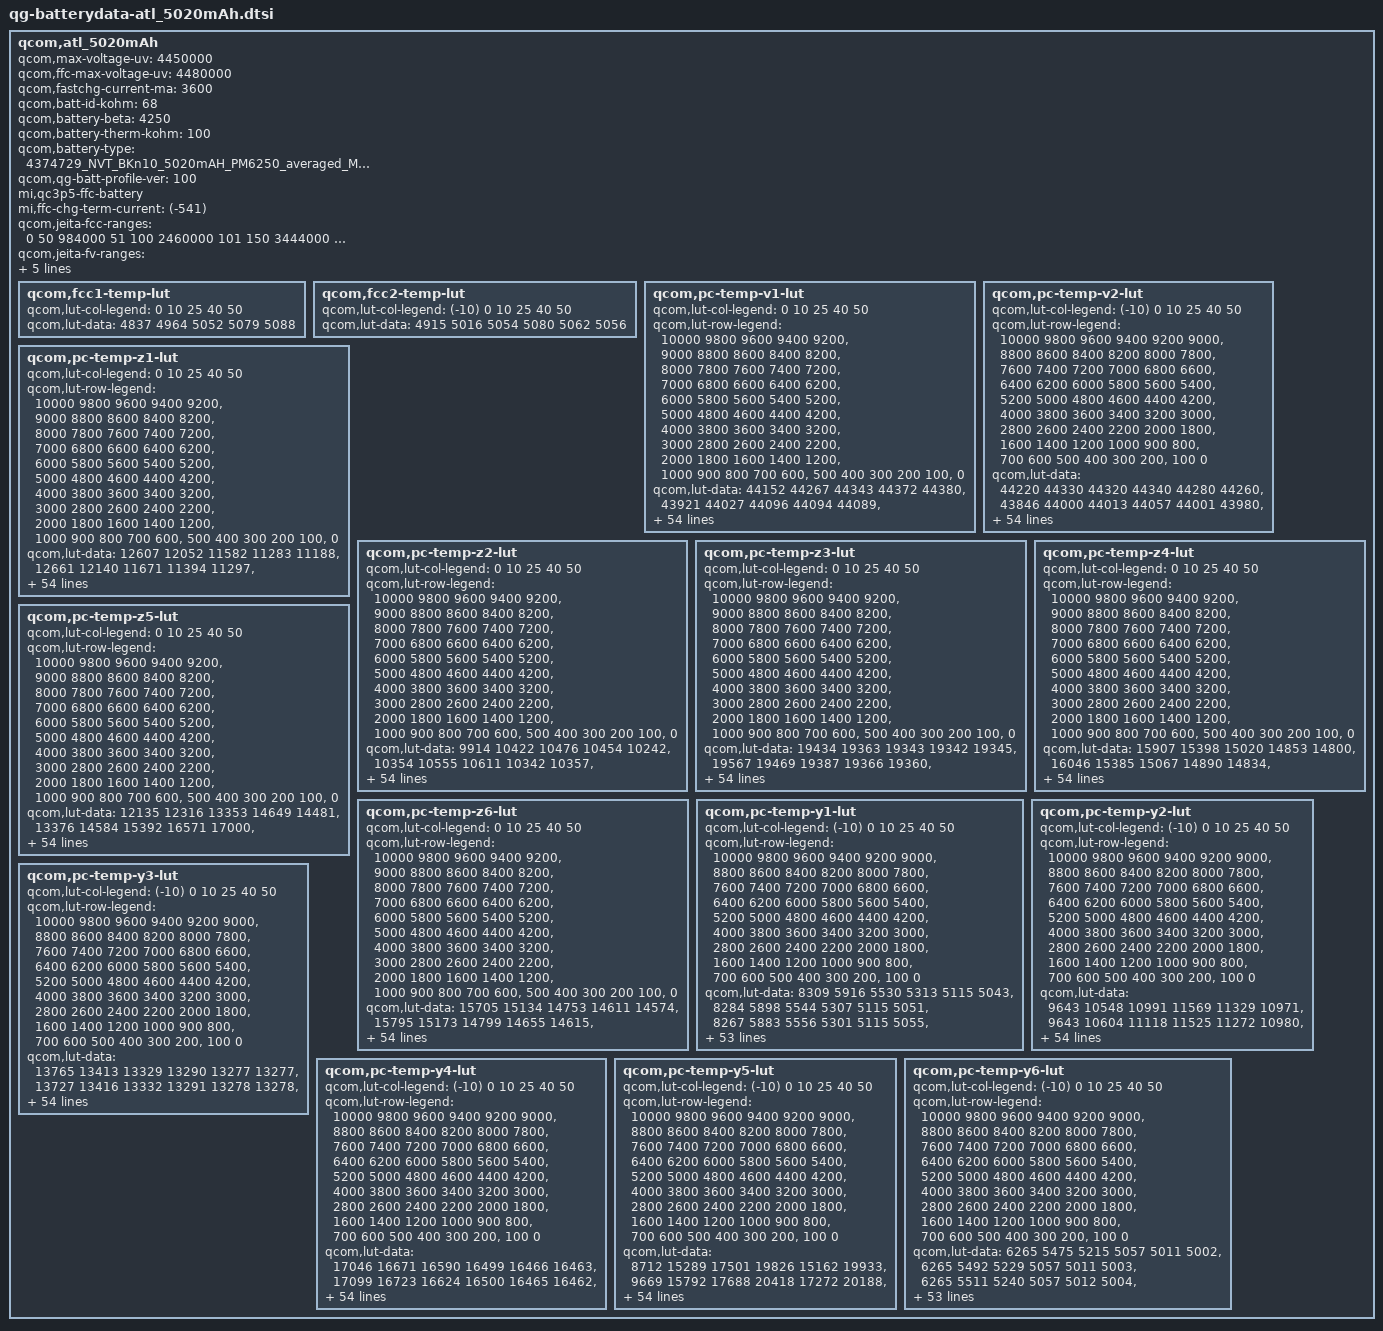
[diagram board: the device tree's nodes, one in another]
/*
 * Copyright (c) 2019, The Linux Foundation. All rights reserved.
 * Copyright (C) 2020 XiaoMi, Inc.
 *
 * This program is free software; you can redistribute it and/or modify
 * it under the terms of the GNU General Public License version 2 and
 * only version 2 as published by the Free Software Foundation.
 *
 * This program is distributed in the hope that it will be useful,
 * but WITHOUT ANY WARRANTY; without even the implied warranty of
 * MERCHANTABILITY or FITNESS FOR A PARTICULAR PURPOSE.  See the
 * GNU General Public License for more details.
 */

qcom,atl_5020mAh {
	qcom,max-voltage-uv = <4450000>;
	qcom,ffc-max-voltage-uv = <4480000>;
	qcom,fastchg-current-ma = <3600>;
	qcom,batt-id-kohm = <68>;
	qcom,battery-beta = <4250>;
	qcom,battery-therm-kohm = <100>;
	qcom,battery-type =
		"4374729_NVT_BKn10_5020mAH_PM6250_averaged_MasterSlave_Dec27th2019";
	qcom,qg-batt-profile-ver = <100>;
	mi,qc3p5-ffc-battery;
	mi,ffc-chg-term-current = <(-541)>;

	qcom,jeita-fcc-ranges = <0   50   984000
				 51  100  2460000
				 101 150  3444000
				 151 450  3600000
				 451 600  2460000>;

	qcom,jeita-fv-ranges = <0   50   4450000
				51  100  4450000
				101 150  4450000
				151 450  4480000
				451 600  4100000>;

	qcom,step-chg-ranges = <3001000  4250000  3600000
				4250001  4430000  3300000
				4430001  4450000  3000000>;

	qcom,dynamic-fv-ranges = <0   100  4480000
				 101  200  4460000
				 201  300  4440000
				 301  400  4420000
				 401  500  4400000>;

	qcom,fcc1-temp-lut {
		qcom,lut-col-legend = <0 10 25 40 50>;
		qcom,lut-data = <4837 4964 5052 5079 5088>;
	};

	qcom,fcc2-temp-lut {
		qcom,lut-col-legend = <(-10) 0 10 25 40 50>;
		qcom,lut-data = <4915 5016 5054 5080 5062 5056>;
	};

	qcom,pc-temp-v1-lut {
		qcom,lut-col-legend = <0 10 25 40 50>;
		qcom,lut-row-legend = <10000 9800 9600 9400 9200>,
			<9000 8800 8600 8400 8200>,
			<8000 7800 7600 7400 7200>,
			<7000 6800 6600 6400 6200>,
			<6000 5800 5600 5400 5200>,
			<5000 4800 4600 4400 4200>,
			<4000 3800 3600 3400 3200>,
			<3000 2800 2600 2400 2200>,
			<2000 1800 1600 1400 1200>,
			<1000 900 800 700 600>,
			<500 400 300 200 100>,
			<0>;
		qcom,lut-data = <44152 44267 44343 44372 44380>,
			<43921 44027 44096 44094 44089>,
			<43687 43792 43869 43868 43860>,
			<43451 43567 43645 43652 43645>,
			<43214 43345 43421 43432 43425>,
			<42975 43113 43196 43211 43206>,
			<42736 42875 42961 42982 42978>,
			<42496 42634 42718 42743 42740>,
			<42258 42391 42475 42501 42499>,
			<42030 42148 42231 42259 42257>,
			<41810 41912 41990 42017 42015>,
			<41592 41680 41754 41779 41777>,
			<41369 41454 41523 41544 41543>,
			<41146 41234 41298 41315 41314>,
			<40935 41020 41077 41092 41093>,
			<40737 40812 40864 40876 40879>,
			<40544 40609 40658 40671 40672>,
			<40349 40416 40459 40474 40470>,
			<40154 40237 40273 40287 40279>,
			<39976 40067 40106 40116 40107>,
			<39825 39895 39932 39943 39936>,
			<39681 39728 39708 39723 39719>,
			<39529 39546 39451 39454 39452>,
			<39370 39299 39240 39232 39230>,
			<39201 39010 39070 39073 39076>,
			<39000 38831 38926 38938 38946>,
			<38791 38741 38812 38814 38822>,
			<38652 38672 38715 38701 38707>,
			<38561 38593 38623 38599 38601>,
			<38491 38517 38532 38505 38503>,
			<38436 38446 38450 38420 38414>,
			<38392 38377 38377 38342 38332>,
			<38350 38314 38311 38269 38256>,
			<38308 38260 38252 38203 38185>,
			<38269 38214 38201 38144 38121>,
			<38235 38171 38152 38086 38057>,
			<38206 38137 38104 38027 37990>,
			<38170 38100 38057 37966 37920>,
			<38117 38044 37993 37891 37837>,
			<38046 37961 37903 37794 37731>,
			<37956 37863 37798 37686 37615>,
			<37830 37747 37682 37573 37496>,
			<37688 37608 37547 37446 37365>,
			<37527 37434 37382 37283 37194>,
			<37361 37270 37222 37135 37057>,
			<37230 37154 37114 37044 36978>,
			<37200 37121 37077 37013 36950>,
			<37157 37092 37052 36993 36929>,
			<37121 37069 37035 36971 36907>,
			<37087 37030 36994 36919 36844>,
			<37017 36855 36782 36672 36572>,
			<36725 36420 36346 36229 36131>,
			<36210 35834 35768 35651 35549>,
			<35519 35017 34971 34860 34755>,
			<34357 33626 33725 33620 33511>,
			<30000 30000 30000 30000 30000>;
	};

	qcom,pc-temp-v2-lut {
		qcom,lut-col-legend = <(-10) 0 10 25 40 50>;
		qcom,lut-row-legend = <10000 9800 9600 9400 9200 9000>,
			<8800 8600 8400 8200 8000 7800>,
			<7600 7400 7200 7000 6800 6600>,
			<6400 6200 6000 5800 5600 5400>,
			<5200 5000 4800 4600 4400 4200>,
			<4000 3800 3600 3400 3200 3000>,
			<2800 2600 2400 2200 2000 1800>,
			<1600 1400 1200 1000 900 800>,
			<700 600 500 400 300 200>,
			<100 0>;
		qcom,lut-data = <44220 44330 44320 44340 44280 44260>,
			<43846 44000 44013 44057 44001 43980>,
			<43513 43701 43733 43793 43739 43718>,
			<43232 43441 43482 43554 43500 43478>,
			<42999 43217 43263 43338 43283 43261>,
			<42771 42994 43039 43117 43062 43040>,
			<42514 42754 42798 42879 42826 42806>,
			<42248 42509 42550 42635 42584 42567>,
			<42008 42260 42302 42390 42343 42327>,
			<41792 42005 42053 42144 42099 42084>,
			<41586 41753 41808 41903 41859 41845>,
			<41390 41497 41570 41665 41622 41608>,
			<41202 41251 41338 41431 41389 41376>,
			<40989 41055 41111 41202 41160 41148>,
			<40736 40905 40890 40977 40938 40926>,
			<40459 40735 40677 40759 40723 40712>,
			<40159 40484 40477 40550 40517 40505>,
			<39832 40195 40280 40347 40319 40305>,
			<39546 39940 40081 40158 40134 40120>,
			<39320 39709 39880 39979 39958 39945>,
			<39116 39483 39664 39777 39766 39757>,
			<38910 39251 39413 39531 39534 39533>,
			<38704 39027 39163 39284 39297 39305>,
			<38536 38831 38960 39074 39090 39100>,
			<38415 38656 38783 38884 38900 38907>,
			<38317 38495 38626 38726 38742 38748>,
			<38238 38334 38486 38597 38614 38619>,
			<38174 38190 38359 38484 38504 38508>,
			<38115 38105 38239 38377 38400 38403>,
			<38056 38050 38127 38279 38304 38305>,
			<38000 38002 38034 38190 38217 38217>,
			<37943 37954 37956 38109 38141 38139>,
			<37887 37908 37893 38033 38068 38064>,
			<37828 37861 37850 37961 37997 37991>,
			<37768 37816 37818 37893 37927 37919>,
			<37705 37767 37782 37821 37846 37832>,
			<37637 37711 37740 37745 37746 37714>,
			<37563 37649 37692 37666 37641 37592>,
			<37484 37577 37629 37583 37544 37492>,
			<37393 37493 37549 37496 37448 37400>,
			<37292 37398 37451 37406 37355 37309>,
			<37194 37290 37318 37312 37268 37222>,
			<37099 37166 37170 37195 37158 37111>,
			<37014 37022 37006 37053 37013 36956>,
			<36945 36883 36850 36919 36889 36836>,
			<36877 36773 36748 36858 36839 36788>,
			<36840 36732 36709 36844 36830 36778>,
			<36793 36702 36665 36822 36815 36763>,
			<36742 36663 36618 36781 36790 36734>,
			<36679 36622 36519 36692 36704 36626>,
			<36584 36523 36278 36388 36388 36294>,
			<36412 36207 35819 35867 35884 35781>,
			<36107 35577 35149 35176 35223 35104>,
			<35532 34601 34139 34194 34286 34157>,
			<34689 33433 32559 32713 32910 32798>,
			<33552 31613 28186 27744 27717 27697>;
	};

	qcom,pc-temp-z1-lut {
		qcom,lut-col-legend = <0 10 25 40 50>;
		qcom,lut-row-legend = <10000 9800 9600 9400 9200>,
			<9000 8800 8600 8400 8200>,
			<8000 7800 7600 7400 7200>,
			<7000 6800 6600 6400 6200>,
			<6000 5800 5600 5400 5200>,
			<5000 4800 4600 4400 4200>,
			<4000 3800 3600 3400 3200>,
			<3000 2800 2600 2400 2200>,
			<2000 1800 1600 1400 1200>,
			<1000 900 800 700 600>,
			<500 400 300 200 100>,
			<0>;
		qcom,lut-data = <12607 12052 11582 11283 11188>,
			<12661 12140 11671 11394 11297>,
			<12733 12181 11696 11414 11316>,
			<12787 12180 11702 11420 11325>,
			<12788 12178 11703 11420 11329>,
			<12775 12173 11703 11419 11331>,
			<12760 12156 11701 11418 11333>,
			<12739 12141 11691 11418 11335>,
			<12714 12133 11683 11418 11336>,
			<12692 12127 11674 11417 11338>,
			<12669 12120 11668 11417 11339>,
			<12657 12110 11669 11415 11340>,
			<12661 12103 11674 11413 11339>,
			<12668 12106 11675 11411 11339>,
			<12670 12113 11673 11412 11339>,
			<12669 12114 11669 11415 11340>,
			<12666 12107 11668 11415 11340>,
			<12663 12100 11667 11414 11341>,
			<12660 12103 11668 11414 11342>,
			<12656 12108 11673 11415 11343>,
			<12651 12110 11679 11417 11345>,
			<12646 12104 11679 11418 11346>,
			<12646 12098 11678 11419 11347>,
			<12650 12100 11678 11420 11348>,
			<12656 12104 11679 11423 11350>,
			<12662 12106 11682 11426 11352>,
			<12668 12099 11685 11428 11354>,
			<12669 12092 11691 11431 11356>,
			<12668 12096 11695 11433 11357>,
			<12667 12110 11698 11435 11360>,
			<12671 12119 11701 11438 11363>,
			<12683 12125 11704 11442 11367>,
			<12697 12129 11707 11446 11370>,
			<12712 12128 11711 11449 11373>,
			<12725 12125 11717 11452 11376>,
			<12730 12124 11722 11455 11379>,
			<12732 12128 11726 11457 11381>,
			<12733 12138 11731 11460 11384>,
			<12731 12153 11736 11464 11386>,
			<12729 12177 11742 11469 11388>,
			<12733 12198 11749 11474 11390>,
			<12778 12213 11758 11477 11393>,
			<12802 12220 11766 11479 11396>,
			<12807 12217 11768 11482 11399>,
			<12828 12237 11775 11486 11399>,
			<12810 12235 11790 11489 11400>,
			<12836 12215 11786 11488 11398>,
			<12810 12220 11790 11486 11399>,
			<12832 12248 11796 11490 11402>,
			<12842 12253 11793 11496 11405>,
			<12810 12233 11805 11498 11408>,
			<12879 12264 11818 11506 11413>,
			<12874 12261 11827 11517 11421>,
			<12894 12323 11843 11526 11432>,
			<12894 12323 11843 11526 11432>,
			<12894 12323 11843 11526 11432>;
	};

	qcom,pc-temp-z2-lut {
		qcom,lut-col-legend = <0 10 25 40 50>;
		qcom,lut-row-legend = <10000 9800 9600 9400 9200>,
			<9000 8800 8600 8400 8200>,
			<8000 7800 7600 7400 7200>,
			<7000 6800 6600 6400 6200>,
			<6000 5800 5600 5400 5200>,
			<5000 4800 4600 4400 4200>,
			<4000 3800 3600 3400 3200>,
			<3000 2800 2600 2400 2200>,
			<2000 1800 1600 1400 1200>,
			<1000 900 800 700 600>,
			<500 400 300 200 100>,
			<0>;
		qcom,lut-data = <9914 10422 10476 10454 10242>,
			<10354 10555 10611 10342 10357>,
			<10378 10613 10687 10471 10344>,
			<10387 10598 10709 10572 10333>,
			<10379 10565 10669 10552 10335>,
			<10345 10532 10610 10502 10341>,
			<10316 10493 10576 10460 10342>,
			<10296 10461 10551 10421 10338>,
			<10282 10442 10532 10394 10331>,
			<10306 10428 10514 10379 10310>,
			<10460 10422 10503 10370 10279>,
			<10577 10420 10509 10371 10272>,
			<10496 10418 10530 10388 10274>,
			<10329 10434 10539 10398 10275>,
			<10273 10470 10540 10394 10260>,
			<10283 10498 10541 10383 10235>,
			<10299 10518 10556 10364 10232>,
			<10317 10538 10596 10324 10239>,
			<10342 10560 10618 10304 10250>,
			<10366 10582 10623 10314 10262>,
			<10389 10598 10628 10338 10280>,
			<10411 10609 10673 10426 10352>,
			<10432 10619 10766 10654 10561>,
			<10455 10635 10790 10756 10667>,
			<10468 10653 10715 10595 10559>,
			<10469 10658 10646 10410 10423>,
			<10470 10642 10651 10441 10421>,
			<10472 10626 10669 10586 10467>,
			<10480 10626 10674 10644 10485>,
			<10490 10627 10674 10573 10410>,
			<10496 10629 10672 10484 10308>,
			<10501 10632 10662 10439 10250>,
			<10506 10635 10644 10406 10206>,
			<10514 10643 10640 10398 10195>,
			<10522 10657 10652 10411 10226>,
			<10529 10672 10671 10432 10275>,
			<10537 10685 10699 10462 10332>,
			<10546 10699 10737 10506 10398>,
			<10565 10716 10772 10555 10442>,
			<10591 10737 10810 10621 10468>,
			<10613 10752 10831 10669 10488>,
			<10630 10757 10822 10683 10503>,
			<10652 10763 10809 10690 10517>,
			<10684 10778 10814 10683 10545>,
			<10988 10899 10842 10666 10522>,
			<10840 10977 10915 10645 10459>,
			<10408 11008 10880 10566 10447>,
			<10530 11042 10850 10589 10486>,
			<10349 11286 10861 10594 10473>,
			<10364 11465 10902 10684 10585>,
			<10679 11364 10896 10598 10460>,
			<10244 11213 10871 10415 10255>,
			<10589 11080 10777 10339 10196>,
			<10353 10777 10717 10315 10129>,
			<10353 10777 10717 10315 10129>,
			<10353 10777 10717 10315 10129>;
	};

	qcom,pc-temp-z3-lut {
		qcom,lut-col-legend = <0 10 25 40 50>;
		qcom,lut-row-legend = <10000 9800 9600 9400 9200>,
			<9000 8800 8600 8400 8200>,
			<8000 7800 7600 7400 7200>,
			<7000 6800 6600 6400 6200>,
			<6000 5800 5600 5400 5200>,
			<5000 4800 4600 4400 4200>,
			<4000 3800 3600 3400 3200>,
			<3000 2800 2600 2400 2200>,
			<2000 1800 1600 1400 1200>,
			<1000 900 800 700 600>,
			<500 400 300 200 100>,
			<0>;
		qcom,lut-data = <19434 19363 19343 19342 19345>,
			<19567 19469 19387 19366 19360>,
			<19647 19529 19412 19377 19368>,
			<19698 19548 19426 19385 19373>,
			<19719 19559 19433 19392 19379>,
			<19732 19560 19438 19398 19384>,
			<19737 19555 19440 19401 19389>,
			<19734 19552 19442 19404 19393>,
			<19729 19552 19442 19405 19395>,
			<19730 19551 19442 19403 19395>,
			<19743 19551 19441 19400 19392>,
			<19753 19546 19438 19398 19390>,
			<19738 19540 19429 19395 19387>,
			<19703 19532 19422 19393 19384>,
			<19684 19523 19419 19390 19381>,
			<19676 19516 19416 19388 19376>,
			<19671 19513 19414 19383 19373>,
			<19663 19509 19412 19377 19370>,
			<19654 19503 19410 19371 19367>,
			<19646 19495 19406 19366 19362>,
			<19636 19493 19403 19363 19358>,
			<19628 19495 19408 19366 19358>,
			<19627 19497 19422 19380 19365>,
			<19629 19502 19426 19386 19368>,
			<19632 19508 19412 19373 19364>,
			<19637 19510 19399 19359 19359>,
			<19645 19502 19400 19367 19365>,
			<19647 19493 19404 19394 19388>,
			<19644 19492 19410 19405 19399>,
			<19640 19493 19419 19402 19395>,
			<19635 19493 19426 19397 19389>,
			<19628 19497 19425 19392 19384>,
			<19622 19500 19421 19386 19378>,
			<19618 19500 19418 19380 19371>,
			<19615 19498 19413 19374 19363>,
			<19611 19496 19409 19368 19355>,
			<19605 19493 19405 19364 19349>,
			<19599 19489 19401 19359 19344>,
			<19592 19485 19399 19358 19343>,
			<19585 19481 19398 19359 19344>,
			<19579 19476 19397 19359 19346>,
			<19572 19468 19394 19359 19349>,
			<19563 19462 19390 19359 19353>,
			<19548 19459 19387 19360 19357>,
			<19479 19439 19379 19359 19356>,
			<19414 19417 19367 19346 19346>,
			<19262 19402 19366 19344 19342>,
			<19262 19392 19366 19336 19329>,
			<19263 19326 19356 19334 19327>,
			<19263 19312 19346 19329 19322>,
			<19261 19322 19345 19343 19338>,
			<19268 19330 19361 19358 19349>,
			<19313 19320 19350 19357 19351>,
			<19331 19336 19343 19352 19352>,
			<19331 19336 19343 19352 19352>,
			<19331 19336 19343 19352 19352>;
	};

	qcom,pc-temp-z4-lut {
		qcom,lut-col-legend = <0 10 25 40 50>;
		qcom,lut-row-legend = <10000 9800 9600 9400 9200>,
			<9000 8800 8600 8400 8200>,
			<8000 7800 7600 7400 7200>,
			<7000 6800 6600 6400 6200>,
			<6000 5800 5600 5400 5200>,
			<5000 4800 4600 4400 4200>,
			<4000 3800 3600 3400 3200>,
			<3000 2800 2600 2400 2200>,
			<2000 1800 1600 1400 1200>,
			<1000 900 800 700 600>,
			<500 400 300 200 100>,
			<0>;
		qcom,lut-data = <15907 15398 15020 14853 14800>,
			<16046 15385 15067 14890 14834>,
			<15895 15354 15005 14862 14821>,
			<15678 15257 14946 14828 14803>,
			<15511 15110 14899 14803 14786>,
			<15355 15018 14857 14780 14768>,
			<15228 14955 14823 14761 14752>,
			<15136 14905 14794 14744 14736>,
			<15058 14862 14770 14730 14723>,
			<14974 14826 14746 14716 14712>,
			<14877 14798 14729 14704 14703>,
			<14821 14774 14720 14697 14698>,
			<14823 14757 14716 14692 14695>,
			<14827 14744 14711 14688 14692>,
			<14827 14733 14706 14684 14689>,
			<14807 14729 14701 14681 14685>,
			<14784 14726 14697 14678 14682>,
			<14776 14724 14692 14676 14679>,
			<14771 14720 14688 14674 14676>,
			<14765 14715 14686 14670 14670>,
			<14753 14714 14684 14665 14664>,
			<14740 14714 14699 14676 14676>,
			<14737 14714 14740 14722 14731>,
			<14736 14744 14772 14756 14762>,
			<14735 14818 14798 14774 14763>,
			<14763 14845 14813 14785 14764>,
			<14815 14830 14806 14772 14752>,
			<14831 14809 14783 14729 14712>,
			<14828 14792 14762 14704 14689>,
			<14823 14775 14740 14696 14684>,
			<14815 14761 14724 14690 14681>,
			<14801 14750 14718 14687 14677>,
			<14788 14742 14714 14684 14674>,
			<14777 14738 14712 14682 14671>,
			<14767 14735 14709 14679 14668>,
			<14757 14732 14708 14677 14667>,
			<14746 14727 14706 14678 14667>,
			<14736 14723 14705 14678 14669>,
			<14726 14720 14704 14680 14672>,
			<14716 14718 14705 14689 14682>,
			<14710 14716 14705 14696 14690>,
			<14707 14707 14700 14690 14685>,
			<14702 14696 14690 14682 14677>,
			<14690 14686 14684 14681 14681>,
			<14686 14667 14670 14671 14674>,
			<14741 14660 14655 14658 14653>,
			<14903 14668 14649 14654 14648>,
			<14898 14670 14639 14647 14646>,
			<14895 14739 14636 14631 14630>,
			<14892 14751 14638 14627 14623>,
			<14886 14743 14654 14642 14650>,
			<14892 14747 14649 14644 14654>,
			<14867 14767 14661 14649 14659>,
			<14873 14763 14674 14655 14659>,
			<14873 14763 14674 14655 14659>,
			<14873 14763 14674 14655 14659>;
	};

	qcom,pc-temp-z5-lut {
		qcom,lut-col-legend = <0 10 25 40 50>;
		qcom,lut-row-legend = <10000 9800 9600 9400 9200>,
			<9000 8800 8600 8400 8200>,
			<8000 7800 7600 7400 7200>,
			<7000 6800 6600 6400 6200>,
			<6000 5800 5600 5400 5200>,
			<5000 4800 4600 4400 4200>,
			<4000 3800 3600 3400 3200>,
			<3000 2800 2600 2400 2200>,
			<2000 1800 1600 1400 1200>,
			<1000 900 800 700 600>,
			<500 400 300 200 100>,
			<0>;
		qcom,lut-data = <12135 12316 13353 14649 14481>,
			<13376 14584 15392 16571 17000>,
			<14249 16199 16950 17958 18491>,
			<14976 17166 18009 19044 19599>,
			<15619 17875 18637 20022 20802>,
			<16173 18433 19169 20873 21940>,
			<16759 18829 19849 21686 23189>,
			<17367 19323 20620 22430 24592>,
			<18061 20315 21550 23232 26014>,
			<19204 21702 23074 24258 27469>,
			<21295 23005 24274 25365 28867>,
			<22654 24286 24355 26265 29829>,
			<22684 25474 24343 27003 30563>,
			<22688 26462 24360 27759 31008>,
			<22776 27352 24861 28840 31153>,
			<23894 28320 25723 29784 31256>,
			<25445 29568 26919 29680 31671>,
			<26620 30355 28577 28664 33059>,
			<27716 29894 29651 28110 34511>,
			<28585 28834 30084 28355 35704>,
			<29076 28849 30621 28958 36792>,
			<29576 33485 34910 31453 37690>,
			<31458 39139 43758 38162 38519>,
			<37823 42577 45780 41008 38731>,
			<44754 45381 34371 31115 30644>,
			<50722 45766 23799 19709 20486>,
			<56058 38419 23121 20097 20879>,
			<57096 30950 22946 24725 26395>,
			<53213 30431 23230 27622 29837>,
			<48213 30488 26702 28650 30861>,
			<44646 30693 30765 29389 31534>,
			<41402 33632 33042 30122 32142>,
			<40184 37841 34862 30777 32668>,
			<40159 40871 36440 31318 32764>,
			<40142 43602 38049 31844 31624>,
			<39967 44905 38932 32159 30172>,
			<39325 45306 38924 32175 29303>,
			<38901 45516 38858 32177 28612>,
			<39925 45316 38749 32190 28439>,
			<41734 44242 38478 32273 28529>,
			<42131 42641 38016 32340 28712>,
			<40965 38660 36632 31274 29331>,
			<39523 36123 34759 29745 30798>,
			<37869 38661 33507 31709 35026>,
			<30789 38277 33765 32759 36491>,
			<26325 32599 30859 27105 30115>,
			<11847 24462 31199 25375 26420>,
			<11818 22080 33752 23369 21764>,
			<11782 14052 28207 28248 26665>,
			<11759 13373 24273 28193 28741>,
			<11759 13921 21449 29126 27877>,
			<11914 14034 23653 29052 24729>,
			<12471 13256 19478 25138 21862>,
			<12955 13819 17104 19942 19131>,
			<12955 13819 17104 19942 19131>,
			<12955 13819 17104 19942 19131>;
	};

	qcom,pc-temp-z6-lut {
		qcom,lut-col-legend = <0 10 25 40 50>;
		qcom,lut-row-legend = <10000 9800 9600 9400 9200>,
			<9000 8800 8600 8400 8200>,
			<8000 7800 7600 7400 7200>,
			<7000 6800 6600 6400 6200>,
			<6000 5800 5600 5400 5200>,
			<5000 4800 4600 4400 4200>,
			<4000 3800 3600 3400 3200>,
			<3000 2800 2600 2400 2200>,
			<2000 1800 1600 1400 1200>,
			<1000 900 800 700 600>,
			<500 400 300 200 100>,
			<0>;
		qcom,lut-data = <15705 15134 14753 14611 14574>,
			<15795 15173 14799 14655 14615>,
			<15740 15182 14791 14651 14614>,
			<15657 15144 14780 14647 14614>,
			<15581 15071 14762 14641 14612>,
			<15498 15020 14742 14633 14607>,
			<15425 14981 14727 14627 14603>,
			<15364 14949 14713 14621 14600>,
			<15311 14922 14701 14615 14596>,
			<15266 14900 14690 14609 14591>,
			<15227 14881 14680 14602 14586>,
			<15196 14864 14673 14597 14582>,
			<15172 14850 14666 14593 14580>,
			<15153 14838 14661 14590 14577>,
			<15135 14828 14656 14587 14573>,
			<15116 14821 14652 14584 14569>,
			<15100 14817 14649 14580 14565>,
			<15090 14813 14646 14575 14562>,
			<15083 14807 14643 14571 14559>,
			<15075 14802 14641 14567 14554>,
			<15065 14800 14639 14563 14549>,
			<15056 14802 14649 14571 14555>,
			<15055 14805 14675 14599 14582>,
			<15057 14821 14688 14614 14597>,
			<15061 14855 14693 14614 14596>,
			<15079 14867 14695 14614 14595>,
			<15107 14857 14692 14614 14592>,
			<15116 14844 14686 14610 14589>,
			<15115 14837 14681 14606 14585>,
			<15114 14831 14677 14602 14582>,
			<15110 14828 14675 14597 14578>,
			<15102 14826 14672 14593 14574>,
			<15095 14825 14670 14589 14570>,
			<15091 14824 14668 14586 14565>,
			<15088 14824 14665 14581 14559>,
			<15084 14823 14663 14578 14555>,
			<15079 14822 14660 14576 14552>,
			<15076 14821 14659 14574 14550>,
			<15076 14821 14658 14574 14549>,
			<15076 14822 14660 14578 14555>,
			<15077 14823 14660 14582 14559>,
			<15083 14820 14659 14580 14559>,
			<15086 14819 14655 14576 14558>,
			<15082 14819 14652 14577 14562>,
			<15065 14810 14645 14573 14559>,
			<15053 14799 14634 14561 14545>,
			<15050 14795 14631 14558 14541>,
			<15050 14792 14628 14551 14534>,
			<15047 14789 14622 14543 14525>,
			<15051 14790 14619 14539 14519>,
			<15055 14797 14628 14554 14540>,
			<15065 14808 14638 14565 14551>,
			<15086 14818 14642 14569 14556>,
			<15112 14836 14647 14572 14559>,
			<15112 14836 14647 14572 14559>,
			<15112 14836 14647 14572 14559>;
	};

	qcom,pc-temp-y1-lut {
		qcom,lut-col-legend = <(-10) 0 10 25 40 50>;
		qcom,lut-row-legend = <10000 9800 9600 9400 9200 9000>,
			<8800 8600 8400 8200 8000 7800>,
			<7600 7400 7200 7000 6800 6600>,
			<6400 6200 6000 5800 5600 5400>,
			<5200 5000 4800 4600 4400 4200>,
			<4000 3800 3600 3400 3200 3000>,
			<2800 2600 2400 2200 2000 1800>,
			<1600 1400 1200 1000 900 800>,
			<700 600 500 400 300 200>,
			<100 0>;
		qcom,lut-data = <8309 5916 5530 5313 5115 5043>,
			<8284 5898 5544 5307 5115 5051>,
			<8267 5883 5556 5301 5115 5055>,
			<8256 5871 5564 5295 5114 5058>,
			<8251 5863 5568 5290 5112 5059>,
			<8250 5860 5570 5286 5110 5059>,
			<8255 5864 5567 5281 5107 5055>,
			<8266 5870 5562 5278 5104 5049>,
			<8269 5873 5556 5274 5102 5048>,
			<8269 5875 5550 5272 5101 5048>,
			<8269 5876 5547 5271 5100 5047>,
			<8273 5871 5556 5271 5100 5047>,
			<8284 5863 5569 5271 5099 5046>,
			<8288 5862 5569 5271 5099 5046>,
			<8266 5868 5562 5270 5098 5046>,
			<8244 5872 5559 5268 5098 5046>,
			<8251 5872 5562 5266 5098 5047>,
			<8282 5872 5566 5265 5097 5048>,
			<8297 5873 5564 5265 5098 5048>,
			<8282 5874 5555 5267 5101 5049>,
			<8263 5875 5550 5269 5102 5049>,
			<8267 5868 5557 5269 5101 5049>,
			<8296 5858 5566 5269 5099 5049>,
			<8318 5860 5565 5270 5100 5049>,
			<8326 5882 5557 5272 5102 5050>,
			<8331 5898 5554 5274 5104 5052>,
			<8332 5901 5561 5276 5106 5053>,
			<8332 5902 5569 5279 5107 5054>,
			<8333 5901 5570 5282 5109 5056>,
			<8332 5893 5571 5286 5111 5057>,
			<8331 5887 5571 5287 5113 5058>,
			<8328 5887 5573 5288 5115 5061>,
			<8319 5886 5575 5289 5117 5063>,
			<8307 5883 5579 5290 5120 5064>,
			<8290 5872 5584 5294 5123 5065>,
			<8270 5865 5590 5298 5124 5066>,
			<8263 5874 5595 5305 5124 5066>,
			<8264 5891 5599 5310 5124 5067>,
			<8266 5901 5602 5310 5125 5068>,
			<8273 5908 5604 5310 5127 5071>,
			<8290 5911 5603 5310 5129 5073>,
			<8300 5911 5593 5310 5130 5075>,
			<8303 5910 5588 5314 5131 5076>,
			<8306 5890 5596 5324 5132 5075>,
			<8318 5909 5612 5322 5135 5074>,
			<8355 5929 5609 5340 5139 5078>,
			<8369 5948 5607 5337 5138 5078>,
			<8325 5940 5619 5331 5139 5077>,
			<8381 5945 5642 5345 5138 5076>,
			<8350 5923 5639 5347 5139 5078>,
			<8454 5975 5651 5334 5139 5083>,
			<8446 6059 5684 5357 5143 5084>,
			<8442 6129 5725 5377 5149 5088>,
			<8136 6459 5800 5404 5157 5093>,
			<8136 6459 5800 5404 5157 5093>,
			<8136 6459 5800 5404 5157 5093>;
	};

	qcom,pc-temp-y2-lut {
		qcom,lut-col-legend = <(-10) 0 10 25 40 50>;
		qcom,lut-row-legend = <10000 9800 9600 9400 9200 9000>,
			<8800 8600 8400 8200 8000 7800>,
			<7600 7400 7200 7000 6800 6600>,
			<6400 6200 6000 5800 5600 5400>,
			<5200 5000 4800 4600 4400 4200>,
			<4000 3800 3600 3400 3200 3000>,
			<2800 2600 2400 2200 2000 1800>,
			<1600 1400 1200 1000 900 800>,
			<700 600 500 400 300 200>,
			<100 0>;
		qcom,lut-data = <9643 10548 10991 11569 11329 10971>,
			<9643 10604 11118 11525 11272 10980>,
			<9643 10684 11197 11482 11218 10983>,
			<9868 10767 11239 11439 11168 10983>,
			<10192 10833 11256 11396 11121 10980>,
			<10367 10859 11259 11354 11080 10974>,
			<10397 10854 11232 11308 11044 10942>,
			<10412 10843 11182 11266 11012 10896>,
			<10466 10829 11142 11236 10981 10876>,
			<10716 10809 11101 11214 10949 10866>,
			<10928 10798 11083 11194 10926 10855>,
			<10862 10917 11086 11172 10909 10832>,
			<10677 11102 11092 11156 10898 10812>,
			<10610 11115 11114 11155 10898 10813>,
			<10710 10988 11184 11160 10901 10827>,
			<10816 10904 11259 11168 10908 10837>,
			<10627 11013 11332 11182 10921 10840>,
			<9998 11184 11399 11207 10942 10843>,
			<9686 11217 11444 11265 10984 10845>,
			<9681 11208 11481 11373 11060 10846>,
			<9678 11193 11494 11441 11130 10853>,
			<9676 11167 11461 11478 11191 10992>,
			<9675 11125 11419 11498 11236 11152>,
			<9674 11081 11408 11488 11249 11149>,
			<9673 11033 11404 11462 11257 11089>,
			<9672 10954 11399 11456 11258 11065>,
			<9671 10569 11387 11496 11246 11126>,
			<9669 10025 11377 11541 11233 11196>,
			<9668 9847 11380 11559 11260 11208>,
			<9667 9793 11394 11572 11339 11211>,
			<9667 9758 11399 11592 11388 11218>,
			<9666 9729 11394 11633 11406 11250>,
			<9665 9708 11382 11660 11420 11298>,
			<9665 9694 11339 11638 11438 11359>,
			<9664 9685 11232 11593 11457 11431>,
			<9664 9678 11137 11583 11458 11454>,
			<9664 9673 11071 11590 11409 11436>,
			<9663 9669 10999 11595 11361 11401>,
			<9663 9666 10898 11556 11354 11314>,
			<9663 9664 10760 11485 11351 11171>,
			<9662 9663 10547 11458 11350 11133>,
			<9662 9661 10098 11449 11352 11223>,
			<9662 9661 9823 11424 11347 11256>,
			<9661 9660 9725 11360 11299 11204>,
			<9660 9659 9689 11271 11224 11114>,
			<9659 9659 9680 11247 11078 10953>,
			<9658 9658 9672 11251 11102 10899>,
			<9657 9657 9667 11202 11086 10904>,
			<9656 9657 9662 11175 11093 10923>,
			<9654 9655 9659 11194 11142 10919>,
			<9650 9653 9657 11112 11062 10877>,
			<9650 9650 9656 11036 10931 10782>,
			<9649 9649 9653 10896 10892 10705>,
			<9649 9649 9653 10711 10720 10524>,
			<9649 9649 9653 10711 10720 10524>,
			<9649 9649 9653 10711 10720 10524>;
	};

	qcom,pc-temp-y3-lut {
		qcom,lut-col-legend = <(-10) 0 10 25 40 50>;
		qcom,lut-row-legend = <10000 9800 9600 9400 9200 9000>,
			<8800 8600 8400 8200 8000 7800>,
			<7600 7400 7200 7000 6800 6600>,
			<6400 6200 6000 5800 5600 5400>,
			<5200 5000 4800 4600 4400 4200>,
			<4000 3800 3600 3400 3200 3000>,
			<2800 2600 2400 2200 2000 1800>,
			<1600 1400 1200 1000 900 800>,
			<700 600 500 400 300 200>,
			<100 0>;
		qcom,lut-data = <13765 13413 13329 13290 13277 13277>,
			<13727 13416 13332 13291 13278 13278>,
			<13689 13419 13336 13293 13280 13279>,
			<13652 13422 13340 13295 13282 13280>,
			<13621 13425 13343 13296 13283 13281>,
			<13598 13427 13345 13297 13284 13281>,
			<13581 13429 13345 13296 13284 13282>,
			<13569 13431 13346 13296 13284 13282>,
			<13566 13430 13347 13296 13285 13283>,
			<13568 13426 13348 13297 13285 13284>,
			<13569 13423 13349 13297 13285 13284>,
			<13546 13425 13351 13299 13286 13285>,
			<13490 13428 13352 13301 13286 13285>,
			<13468 13424 13351 13302 13286 13285>,
			<13471 13398 13347 13302 13286 13286>,
			<13475 13382 13344 13303 13287 13286>,
			<13481 13384 13343 13303 13289 13286>,
			<13489 13388 13342 13304 13291 13286>,
			<13493 13388 13339 13303 13292 13287>,
			<13492 13379 13337 13303 13293 13288>,
			<13490 13369 13333 13302 13293 13289>,
			<13485 13360 13328 13299 13291 13288>,
			<13472 13353 13322 13296 13288 13286>,
			<13466 13348 13318 13293 13285 13283>,
			<13468 13346 13316 13290 13282 13280>,
			<13474 13343 13314 13289 13280 13279>,
			<13485 13335 13312 13289 13280 13279>,
			<13511 13326 13310 13289 13280 13279>,
			<13542 13326 13309 13288 13279 13279>,
			<13570 13336 13308 13288 13279 13279>,
			<13599 13348 13307 13288 13279 13278>,
			<13633 13356 13304 13288 13279 13278>,
			<13672 13366 13301 13288 13279 13277>,
			<13714 13381 13303 13288 13279 13278>,
			<13758 13410 13308 13288 13280 13279>,
			<13803 13446 13313 13287 13280 13280>,
			<13847 13485 13317 13287 13280 13279>,
			<13889 13533 13321 13287 13280 13278>,
			<13930 13592 13326 13286 13279 13278>,
			<13969 13669 13331 13285 13279 13279>,
			<14005 13749 13338 13285 13279 13279>,
			<14043 13828 13349 13288 13282 13281>,
			<14080 13903 13366 13289 13282 13282>,
			<14127 13964 13394 13290 13280 13278>,
			<14199 14035 13433 13291 13277 13277>,
			<14317 14055 13454 13291 13282 13281>,
			<14387 14128 13506 13295 13285 13284>,
			<14446 14224 13578 13298 13288 13286>,
			<14664 14335 13684 13302 13290 13287>,
			<15141 14545 13869 13306 13289 13285>,
			<16920 15099 14112 13304 13284 13283>,
			<21105 17956 14426 13308 13285 13284>,
			<32731 28830 15373 13317 13290 13288>,
			<65535 65535 21034 13334 13297 13297>,
			<65535 65535 21034 13334 13297 13297>,
			<65535 65535 21034 13334 13297 13297>;
	};

	qcom,pc-temp-y4-lut {
		qcom,lut-col-legend = <(-10) 0 10 25 40 50>;
		qcom,lut-row-legend = <10000 9800 9600 9400 9200 9000>,
			<8800 8600 8400 8200 8000 7800>,
			<7600 7400 7200 7000 6800 6600>,
			<6400 6200 6000 5800 5600 5400>,
			<5200 5000 4800 4600 4400 4200>,
			<4000 3800 3600 3400 3200 3000>,
			<2800 2600 2400 2200 2000 1800>,
			<1600 1400 1200 1000 900 800>,
			<700 600 500 400 300 200>,
			<100 0>;
		qcom,lut-data = <17046 16671 16590 16499 16466 16463>,
			<17099 16723 16624 16500 16465 16462>,
			<17153 16809 16667 16501 16464 16460>,
			<17202 16902 16710 16501 16462 16458>,
			<17237 16977 16743 16501 16460 16457>,
			<17253 17008 16755 16501 16460 16457>,
			<17247 17004 16751 16500 16460 16457>,
			<17232 16996 16743 16499 16460 16458>,
			<17215 16989 16735 16499 16460 16458>,
			<17187 16984 16724 16500 16462 16457>,
			<17166 16978 16719 16502 16464 16457>,
			<17220 16966 16719 16504 16466 16458>,
			<17352 16953 16719 16507 16469 16460>,
			<17399 16973 16725 16512 16472 16461>,
			<17304 17097 16750 16518 16476 16464>,
			<17168 17178 16775 16527 16481 16467>,
			<17072 17114 16798 16540 16485 16471>,
			<16987 16996 16815 16558 16491 16476>,
			<16920 16928 16815 16585 16503 16486>,
			<16871 16888 16806 16623 16527 16502>,
			<16829 16848 16790 16634 16537 16509>,
			<16783 16797 16733 16601 16529 16506>,
			<16731 16745 16662 16557 16514 16501>,
			<16706 16697 16623 16524 16495 16489>,
			<16710 16652 16596 16495 16470 16467>,
			<16715 16618 16576 16485 16461 16457>,
			<16716 16596 16562 16483 16461 16457>,
			<16715 16580 16550 16483 16462 16456>,
			<16715 16579 16531 16484 16465 16457>,
			<16717 16587 16508 16488 16470 16461>,
			<16723 16597 16498 16492 16476 16467>,
			<16729 16612 16497 16497 16484 16475>,
			<16734 16631 16496 16501 16491 16484>,
			<16739 16646 16501 16501 16497 16492>,
			<16744 16658 16518 16501 16502 16499>,
			<16749 16670 16537 16499 16503 16501>,
			<16754 16687 16560 16486 16490 16486>,
			<16759 16703 16582 16475 16476 16471>,
			<16763 16709 16600 16471 16470 16471>,
			<16759 16712 16617 16469 16465 16474>,
			<16746 16713 16627 16471 16465 16477>,
			<16740 16707 16634 16483 16472 16487>,
			<16741 16697 16638 16490 16473 16488>,
			<16743 16686 16641 16494 16459 16461>,
			<16754 16675 16644 16488 16446 16441>,
			<16775 16652 16635 16487 16454 16459>,
			<16781 16656 16650 16502 16477 16493>,
			<16764 16666 16673 16520 16509 16530>,
			<16778 16684 16763 16552 16549 16565>,
			<16808 16708 16796 16583 16556 16556>,
			<17097 16745 16828 16557 16485 16486>,
			<17885 17090 16840 16546 16473 16472>,
			<21479 19658 17004 16571 16476 16469>,
			<51338 53158 20525 16626 16490 16484>,
			<51338 53158 20525 16626 16490 16484>,
			<51338 53158 20525 16626 16490 16484>;
	};

	qcom,pc-temp-y5-lut {
		qcom,lut-col-legend = <(-10) 0 10 25 40 50>;
		qcom,lut-row-legend = <10000 9800 9600 9400 9200 9000>,
			<8800 8600 8400 8200 8000 7800>,
			<7600 7400 7200 7000 6800 6600>,
			<6400 6200 6000 5800 5600 5400>,
			<5200 5000 4800 4600 4400 4200>,
			<4000 3800 3600 3400 3200 3000>,
			<2800 2600 2400 2200 2000 1800>,
			<1600 1400 1200 1000 900 800>,
			<700 600 500 400 300 200>,
			<100 0>;
		qcom,lut-data = <8712 15289 17501 19826 15162 19933>,
			<9669 15792 17688 20418 17272 20188>,
			<11930 16273 18058 20674 18707 20496>,
			<14351 16730 18483 20671 19586 20792>,
			<16406 17160 18835 20483 20024 21014>,
			<17569 17560 18986 20184 20137 21098>,
			<17843 18007 19000 19404 19668 21071>,
			<17991 18378 19008 18406 18862 21007>,
			<18454 18365 18968 17835 18366 20896>,
			<20364 17929 18756 17414 18026 20663>,
			<21967 17494 18517 17263 17660 20363>,
			<21292 17201 18341 17325 17192 19989>,
			<19460 16980 18126 17402 16699 19520>,
			<18921 16985 17527 17277 16221 18952>,
			<22124 17271 16184 16758 15723 18238>,
			<25541 17740 15531 16249 15531 17549>,
			<24340 19008 16338 15746 15774 16883>,
			<19564 20778 17819 15390 16068 16305>,
			<17232 21755 19394 15473 16018 15931>,
			<17402 22390 21319 15925 15744 15637>,
			<17616 22727 22575 16748 15696 15602>,
			<17236 22809 23156 19789 18185 18233>,
			<15390 22863 23563 22512 20985 21304>,
			<13804 23236 23938 22439 21115 21543>,
			<12984 24705 24278 21907 20686 21294>,
			<12417 25656 24392 21739 20200 21017>,
			<12354 21468 24257 21911 19660 20767>,
			<12555 14816 24106 22065 19073 20437>,
			<12776 13493 24349 21978 18428 19713>,
			<12904 13633 25127 21777 17751 18466>,
			<13016 13726 25307 21769 17543 17640>,
			<13176 13633 21886 22302 17656 17161>,
			<13422 13484 18257 23053 17884 16892>,
			<13694 13544 18287 23868 18504 17592>,
			<13959 14066 19112 24779 19805 19659>,
			<14223 14495 19472 25455 21119 21003>,
			<14398 14602 19512 26040 22687 21628>,
			<14523 14674 19530 26326 23714 22096>,
			<14596 14795 19521 24345 23262 22470>,
			<14554 14993 19480 21013 22174 22774>,
			<14369 15103 19322 20330 22005 23287>,
			<14116 15065 18046 20348 23434 24415>,
			<13593 14961 16712 20117 23875 24811>,
			<13298 14542 15673 19482 22883 24683>,
			<13406 14167 14664 19615 18468 19832>,
			<13533 13783 14503 19761 18895 18420>,
			<13558 13685 14334 19909 18956 17068>,
			<13422 14030 14181 19440 18030 15952>,
			<13637 13718 13639 18668 17083 15494>,
			<13639 14207 14258 18736 16567 14834>,
			<12032 14042 14393 18831 16953 16325>,
			<10472 11452 13842 20959 17437 16690>,
			<9377 9480 12362 20858 19605 17261>,
			<8878 8855 9797 20569 24412 24826>,
			<8878 8855 9797 20569 24412 24826>,
			<8878 8855 9797 20569 24412 24826>;
	};

	qcom,pc-temp-y6-lut {
		qcom,lut-col-legend = <(-10) 0 10 25 40 50>;
		qcom,lut-row-legend = <10000 9800 9600 9400 9200 9000>,
			<8800 8600 8400 8200 8000 7800>,
			<7600 7400 7200 7000 6800 6600>,
			<6400 6200 6000 5800 5600 5400>,
			<5200 5000 4800 4600 4400 4200>,
			<4000 3800 3600 3400 3200 3000>,
			<2800 2600 2400 2200 2000 1800>,
			<1600 1400 1200 1000 900 800>,
			<700 600 500 400 300 200>,
			<100 0>;
		qcom,lut-data = <6265 5475 5215 5057 5011 5002>,
			<6265 5492 5229 5057 5011 5003>,
			<6265 5511 5240 5057 5012 5004>,
			<6265 5527 5248 5057 5012 5004>,
			<6265 5538 5253 5057 5013 5005>,
			<6265 5543 5255 5057 5013 5005>,
			<6255 5540 5253 5056 5013 5006>,
			<6231 5535 5248 5055 5013 5006>,
			<6216 5530 5243 5055 5013 5006>,
			<6207 5522 5238 5055 5014 5006>,
			<6200 5516 5235 5055 5015 5007>,
			<6197 5510 5233 5056 5016 5007>,
			<6195 5505 5232 5058 5016 5008>,
			<6191 5508 5233 5060 5018 5009>,
			<6173 5528 5236 5062 5019 5010>,
			<6146 5542 5239 5065 5021 5011>,
			<6112 5527 5244 5069 5023 5012>,
			<6068 5500 5248 5074 5026 5014>,
			<6040 5481 5248 5082 5031 5017>,
			<6029 5467 5244 5091 5038 5023>,
			<6021 5454 5237 5094 5041 5025>,
			<6012 5438 5217 5083 5037 5023>,
			<6001 5423 5194 5068 5030 5020>,
			<5996 5415 5182 5057 5022 5015>,
			<6003 5410 5174 5047 5013 5006>,
			<6018 5406 5169 5044 5009 5002>,
			<6035 5402 5166 5043 5009 5002>,
			<6058 5398 5164 5043 5009 5002>,
			<6084 5401 5160 5043 5010 5003>,
			<6110 5423 5156 5045 5011 5004>,
			<6137 5451 5154 5046 5013 5005>,
			<6167 5478 5156 5049 5015 5007>,
			<6201 5509 5160 5051 5018 5009>,
			<6236 5546 5167 5051 5020 5012>,
			<6272 5592 5181 5052 5022 5016>,
			<6310 5643 5197 5052 5023 5016>,
			<6346 5698 5219 5049 5019 5012>,
			<6382 5758 5244 5046 5015 5007>,
			<6416 5823 5272 5045 5013 5007>,
			<6446 5895 5304 5044 5012 5008>,
			<6473 5966 5339 5045 5012 5010>,
			<6504 6033 5378 5052 5016 5014>,
			<6540 6096 5421 5056 5017 5015>,
			<6587 6147 5472 5059 5011 5005>,
			<6656 6208 5539 5061 5006 4999>,
			<6769 6228 5580 5063 5012 5007>,
			<6835 6289 5653 5071 5022 5019>,
			<6887 6373 5739 5079 5033 5031>,
			<7085 6474 5871 5092 5045 5042>,
			<7511 6657 6057 5104 5047 5039>,
			<9044 7138 6278 5096 5023 5017>,
			<12404 9467 6545 5100 5021 5014>,
			<21635 17909 7371 5124 5026 5017>,
			<53403 61933 12578 5169 5037 5028>,
			<53403 61933 12578 5169 5037 5028>,
			<53403 61933 12578 5169 5037 5028>;
	};

};
